# STM8AL31E89 register map
Vendor: STMicroelectronics; Series: STM8L/STM8AL, high/medium+ density; File version: 1.0
CPU: other r1p0, big endian, no MPU, no FPU, 4 interrupt priority bits
Registers are 8-bit, read-write, reset 0x0 unless marked. A register's access mark holds for its fields unless they carry their own. Offsets are from the block's base; [hi:lo] are bit positions; lines under a group give offsets from that group; {n}, {i} and the like mark numbered series.

## PORTD
Base 0x0000500F
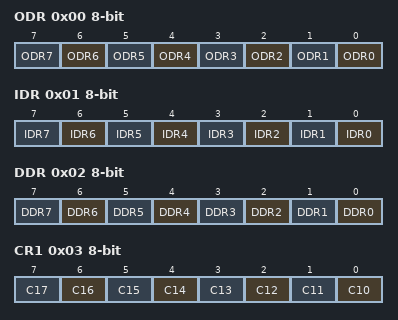
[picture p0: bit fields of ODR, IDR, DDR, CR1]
0x00 ODR — Port D data output latch register
  [n] ODR{n} (n=0..7)
0x01 IDR — Port D input pin value register
  [n] IDR{n} (n=0..7)
0x02 DDR — Port D data direction register
  [n] DDR{n} (n=0..7)
0x03 CR1 — Port D control register 1
  [n-10] C{n} (n=10..17)
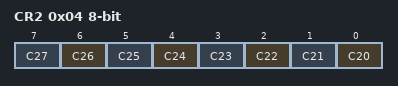
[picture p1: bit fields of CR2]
0x04 CR2 — Port D control register 2
  [n-20] C{n} (n=20..27)

## PORTE
Base 0x00005014
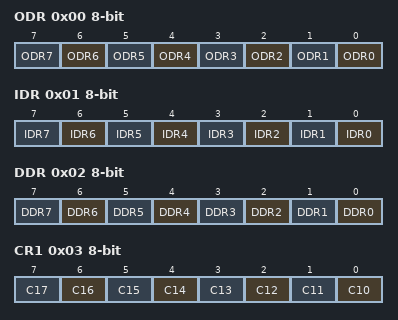
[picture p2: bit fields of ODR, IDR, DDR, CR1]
0x00 ODR — Port E data output latch register
  [n] ODR{n} (n=0..7)
0x01 IDR — Port E input pin value register
  [n] IDR{n} (n=0..7)
0x02 DDR — Port E data direction register
  [n] DDR{n} (n=0..7)
0x03 CR1 — Port E control register 1
  [n-10] C{n} (n=10..17)
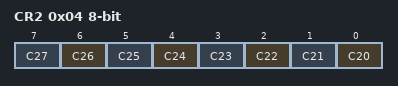
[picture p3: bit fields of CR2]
0x04 CR2 — Port E control register 2
  [n-20] C{n} (n=20..27)

## PORTF
Base 0x00005019
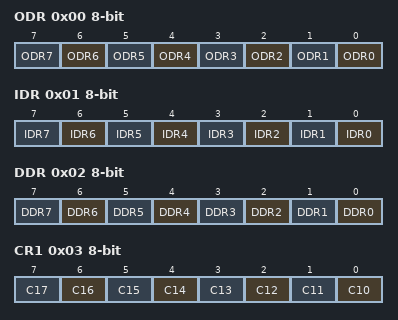
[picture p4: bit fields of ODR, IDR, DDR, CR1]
0x00 ODR — Port F data output latch register
  [n] ODR{n} (n=0..7)
0x01 IDR — Port F input pin value register
  [n] IDR{n} (n=0..7)
0x02 DDR — Port F data direction register
  [n] DDR{n} (n=0..7)
0x03 CR1 — Port F control register 1
  [n-10] C{n} (n=10..17)
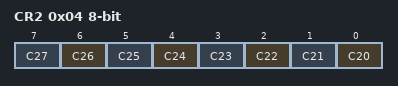
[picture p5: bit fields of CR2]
0x04 CR2 — Port F control register 2
  [n-20] C{n} (n=20..27)

## PORTG
Base 0x0000501E
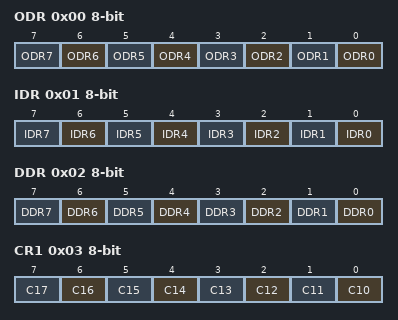
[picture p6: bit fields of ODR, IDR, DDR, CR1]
0x00 ODR — Port G data output latch register
  [n] ODR{n} (n=0..7)
0x01 IDR — Port G input pin value register
  [n] IDR{n} (n=0..7)
0x02 DDR — Port G data direction register
  [n] DDR{n} (n=0..7)
0x03 CR1 — Port G control register 1
  [n-10] C{n} (n=10..17)
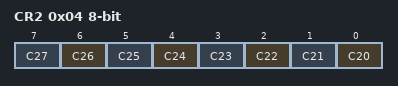
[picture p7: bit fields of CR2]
0x04 CR2 — Port G control register 2
  [n-20] C{n} (n=20..27)

## PORTH
Base 0x00005023
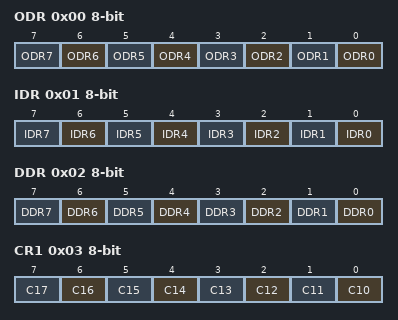
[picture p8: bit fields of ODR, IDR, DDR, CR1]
0x00 ODR — Port H data output latch register
  [n] ODR{n} (n=0..7)
0x01 IDR — Port H input pin value register
  [n] IDR{n} (n=0..7)
0x02 DDR — Port H data direction register
  [n] DDR{n} (n=0..7)
0x03 CR1 — Port H control register 1
  [n-10] C{n} (n=10..17)
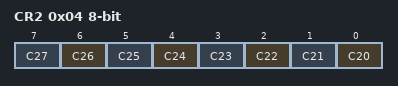
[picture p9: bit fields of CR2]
0x04 CR2 — Port H control register 2
  [n-20] C{n} (n=20..27)

## PORTI
Base 0x00005028
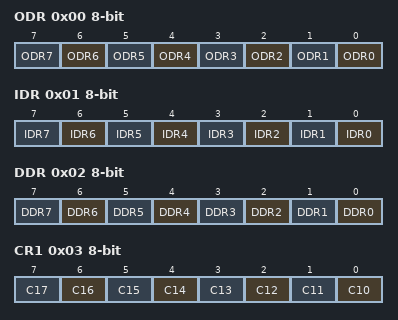
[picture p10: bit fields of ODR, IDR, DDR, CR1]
0x00 ODR — Port I data output latch register
  [n] ODR{n} (n=0..7)
0x01 IDR — Port I input pin value register
  [n] IDR{n} (n=0..7)
0x02 DDR — Port I data direction register
  [n] DDR{n} (n=0..7)
0x03 CR1 — Port I control register 1
  [n-10] C{n} (n=10..17)
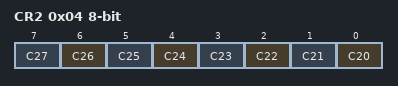
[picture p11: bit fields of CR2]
0x04 CR2 — Port I control register 2
  [n-20] C{n} (n=20..27)

## RI
Base 0x00005431
0x00 ICR1 — Timer input capture routing register 1
  [4:0] IC2CS
0x01 ICR2 — Timer input capture routing register 2
  [4:0] IC3CS
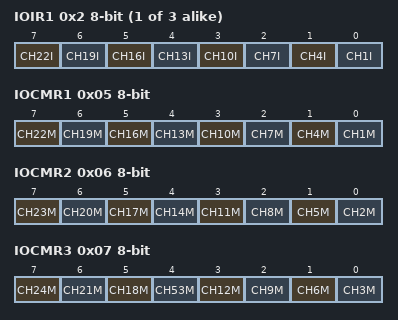
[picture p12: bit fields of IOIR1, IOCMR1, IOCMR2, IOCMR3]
{0x1+i} IOIR{i} (i=1..3) — I/O input register {i}
  [7] CH{i+21}I, [6] CH{i+18}I, [5] CH{i+15}I, [4] CH{i+12}I, [3] CH{i+9}I, [2] CH{i+6}I, [1] CH{i+3}I, [0] CH{i}I
0x05 IOCMR1 — I/O control mode register 1
  [7] CH22M, [6] CH19M, [5] CH16M, [4] CH13M, [3] CH10M, [2] CH7M, [1] CH4M, [0] CH1M
0x06 IOCMR2 — I/O control mode register 2
  [7] CH23M, [6] CH20M, [5] CH17M, [4] CH14M, [3] CH11M, [2] CH8M, [1] CH5M, [0] CH2M
0x07 IOCMR3 — I/O control mode register 3
  [7] CH24M, [6] CH21M, [5] CH18M, [4] CH53M, [3] CH12M, [2] CH9M, [1] CH6M, [0] CH3M
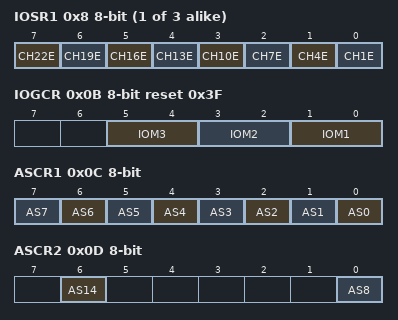
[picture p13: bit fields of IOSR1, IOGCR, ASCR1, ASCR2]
{0x7+i} IOSR{i} (i=1..3) — I/O switch register {i}
  [7] CH{i+21}E, [6] CH{i+18}E, [5] CH{i+15}E, [4] CH{i+12}E, [3] CH{i+9}E, [2] CH{i+6}E, [1] CH{i+3}E, [0] CH{i}E
0x0B IOGCR reset 0x3F — I/O group control register
  [5:4] IOM3, [3:2] IOM2, [1:0] IOM1
0x0C ASCR1 — Analog switch register 1
  [n] AS{n} (n=0..7)
0x0D ASCR2 — Analog switch register 2
  [6] AS14, [0] AS8
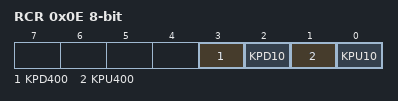
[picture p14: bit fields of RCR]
0x0E RCR — Resistor control register 1
  [3] KPD400, [2] KPD10, [1] KPU400, [0] KPU10

## RST
Base 0x000050B0
0x00 CR — Reset control register
  [7:0] RSTPIN_KEY
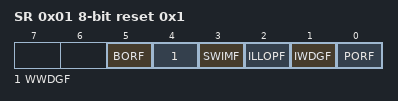
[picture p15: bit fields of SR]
0x01 SR reset 0x1 — Reset status register
  [5] BORF, [4] WWDGF, [3] SWIMF, [2] ILLOPF, [1] IWDGF, [0] PORF

## RTC
Base 0x00005140
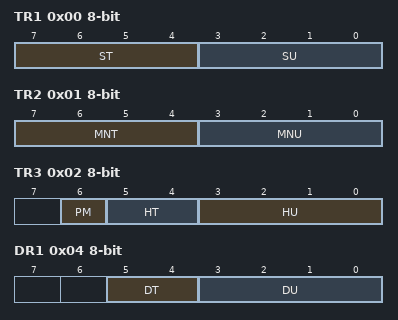
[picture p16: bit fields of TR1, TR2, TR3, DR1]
0x00 TR1 — Time register 1
  [7:4] ST, [3:0] SU
0x01 TR2 — Time register 2
  [7:4] MNT, [3:0] MNU
0x02 TR3 — Time register 3
  [6] PM, [5:4] HT, [3:0] HU
0x04 DR1 — Date register 1
  [5:4] DT, [3:0] DU
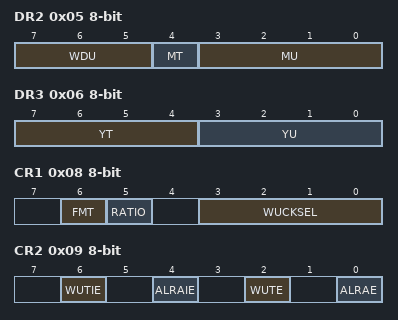
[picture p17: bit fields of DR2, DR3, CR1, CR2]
0x05 DR2 — Date register 2
  [7:5] WDU, [4] MT, [3:0] MU
0x06 DR3 — Date register 3
  [7:4] YT, [3:0] YU
0x08 CR1 — Control register 1
  [6] FMT, [5] RATIO, [3:0] WUCKSEL
0x09 CR2 — Control register 2
  [6] WUTIE, [4] ALRAIE, [2] WUTE, [0] ALRAE
0x0A CR3 — Control register 3
  [7] COE, [6:5] OSEL, [4] POL, [2] BCK, [1] SUB1H, [0] ADD1H
0x0C ISR1 — Initialization and status register 1
  [7] INIT, [6] INITF, [5] RSF, [4] INITS, [3] SHPF, [2] WUTWF, [1] RECALPF, [0] ALRAWF
0x0D ISR2 — Initialization and Status register 2
  [7] TAMP3F, [6] TAMP2F, [5] TAMP1F, [2] WUTF, [0] ALRAF
0x10 SPRERH — Synchronous prescaler register high
  [n-8] PREDIV_S{n} (n=8..14)
0x11 SPRERL — Synchronous prescaler register low
  [n] PREDIV_S{n} (n=0..7)
0x12 APRER — Asynchronous prescaler register
  [6:0] PREDIV_A
0x14 WUTRH — Wakeup timer register high
  [n-8] WUT{n} (n=8..15)
0x15 WUTRL — Wakeup timer register low
  [n] WUT{n} (n=0..7)
0x17 SSRL — Subsecond register low
  [n] SS{n} (n=0..7)
0x18 SSRH — Subsecond register high
  [n-8] SS{n} (n=8..15)
0x19 WPR — Write protection register
  [n] KEY{n} (n=0..7)
0x1A SHIFTRH — Shift register high
  [7] ADDIS, [n-8] SUBFS{n} (n=8..14)
0x1B SHIFTRL — Shift register low
  [n] SUBFS{n} (n=0..7)
0x1C ALRMAR1 — Alarm A register 1
  [7] MSK1, [6:4] ALST, [3:0] ALSU
0x1D ALRMAR2 — Alarm A register 2
  [7] MSK2, [6:4] ALMNT, [3:0] ALMNU
0x1E ALRMAR3 — Alarm A register 3
  [7] MSK3, [6] PM, [5:4] ALHT, [3:0] ALHU
0x1F ALRMAR4 — Alarm A register 4
  [7] MSK4, [6] WDSEL, [5:4] ALDT, [3:0] ALDU
0x24 ALRMASSRH — Alarm A subsecond register high
  [n-8] ALSS{n} (n=8..14)
0x25 ALRMASSRL — Alarm A subsecond register low
  [n] ALSS{n} (n=0..7)
0x26 ALRMASSMSKR — Alarm A masking register
  [n] MASKSS{n} (n=0..3)
0x2A CALRH — Calibration register high
  [7] CALP, [6] CALW8, [5] CALW16, [0] CALM8
0x2B CALRL — Calibration register low
  [n] CALM{n} (n=0..7)
0x2C TCR1 — Tamper control register 1
  [6] TAMP3LEVEL, [5] TAMP3E, [4] TAMP2LEVEL, [3] TAMP2E, [2] TAMP1LEVEL, [1] TAMP1E, [0] TAMPIE
0x2D TCR2 — Tamper control register 2
  [7] TAMPPUDIS, [6:5] TAMPPRCH, [4:3] TAMPFLT, [2:0] TAMPFREQ
0x50 CSS_LSE_CSR — CSS on LSE control and status register
  [4] SWITCHF, [3] CSSF, [2] CSSIE, [1] SWITCHEN, [0] CSSEN
